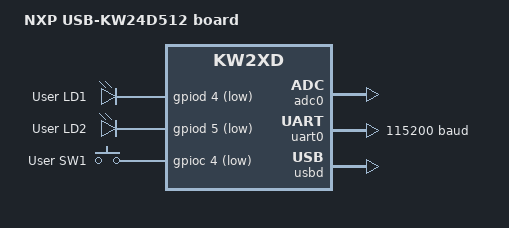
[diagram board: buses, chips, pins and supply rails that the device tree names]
/* SPDX-License-Identifier: Apache-2.0 */

/dts-v1/;

#include <nxp/MKW24D512VHA5.dtsi>

/ {
	model = "NXP USB-KW24D512 board";
	compatible = "nxp,usb-kw24d512", "nxp,kw24d512", "nxp,kw2xd";

	aliases {
		led0 = &led_0;
		led1 = &led_1;
		sw0 = &user_button_1;
	};

	chosen {
		zephyr,sram = &sram0;
		zephyr,flash = &flash0;
		zephyr,console = &uart0;
		zephyr,shell-uart = &uart0;
		zephyr,uart-pipe = &uart0;
	};

	leds {
		compatible = "gpio-leds";
		led_0: led_0 {
			gpios = <&gpiod 4 GPIO_ACTIVE_LOW>;
			label = "User LD1";
		};
		led_1: led_1 {
			gpios = <&gpiod 5 GPIO_ACTIVE_LOW>;
			label = "User LD2";
		};
	};

	gpio_keys {
		compatible = "gpio-keys";
		user_button_1: button_0 {
			label = "User SW1";
			gpios = <&gpioc 4 GPIO_ACTIVE_LOW>;
		};
	};
};

&sim {
	pllfll-select = <KINETIS_SIM_PLLFLLSEL_MCGPLLCLK>;
	er32k-select = <KINETIS_SIM_ER32KSEL_RTC>;
};

&cpu0 {
	clock-frequency = <48000000>;
};

&adc0 {
	status = "okay";
};

&uart0 {
	status = "okay";
	current-speed = <115200>;
	pinctrl-0 = <&UART0_RX_PTA1 &UART0_TX_PTA2>;
};

&usbd {
	compatible = "nxp,kinetis-usbd";
	status = "okay";
	num-bidir-endpoints = <8>;
};

&gpioa {
	status = "okay";
};

&gpiob {
	status = "okay";
};

&gpioc {
	status = "okay";
};

&gpiod {
	status = "okay";
};

&gpioe {
	status = "okay";
};
